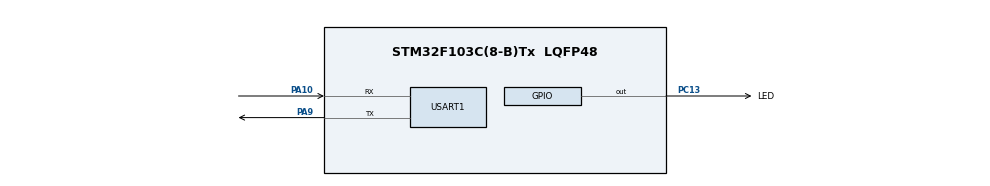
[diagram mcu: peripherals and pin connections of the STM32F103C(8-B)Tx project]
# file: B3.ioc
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Dma.Request0=USART1_TX
Dma.USART1_TX.0.Direction=DMA_MEMORY_TO_PERIPH
Dma.USART1_TX.0.Instance=DMA1_Channel4
Dma.USART1_TX.0.MemDataAlignment=DMA_MDATAALIGN_BYTE
Dma.USART1_TX.0.MemInc=DMA_MINC_ENABLE
Dma.USART1_TX.0.Mode=DMA_NORMAL
Dma.USART1_TX.0.PeriphDataAlignment=DMA_PDATAALIGN_BYTE
Dma.USART1_TX.0.PeriphInc=DMA_PINC_DISABLE
Dma.USART1_TX.0.Priority=DMA_PRIORITY_HIGH
Mcu.Family=STM32F1
Mcu.Name=STM32F103C(8-B)Tx
Mcu.Package=LQFP48
NVIC.DMA1_Channel4_IRQn=true\:0\:0\:false\:false\:true\:false\:true\:true
NVIC.PriorityGroup=NVIC_PRIORITYGROUP_4
NVIC.TIM2_IRQn=true\:0\:0\:false\:false\:true\:true\:true\:true
NVIC.USART1_IRQn=true\:0\:0\:false\:false\:true\:false\:true\:true
PA10.Mode=Asynchronous
PA10.Signal=USART1_RX
PA13.Mode=Serial_Wire
PA13.Signal=SYS_JTMS-SWDIO
PA14.Mode=Serial_Wire
PA14.Signal=SYS_JTCK-SWCLK
PA9.Mode=Asynchronous
PA9.Signal=USART1_TX
PC13-TAMPER-RTC.GPIO_Label=LED
PC13-TAMPER-RTC.GPIO_Speed=GPIO_SPEED_FREQ_MEDIUM
PC13-TAMPER-RTC.Signal=GPIO_Output
ProjectManager.HeapSize=0x200
ProjectManager.StackSize=0x400
ProjectManager.TargetToolchain=STM32CubeIDE
RCC.APB1Freq_Value=8000000
RCC.APB2Freq_Value=8000000
TIM2.AutoReloadPreload=TIM_AUTORELOAD_PRELOAD_ENABLE
TIM2.Period=499
TIM2.Prescaler=7999
USART1.VirtualMode=VM_ASYNC
VP_TIM2_VS_ClockSourceINT.Mode=Internal
board=custom

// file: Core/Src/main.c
/* USER CODE BEGIN Header */
/**
  ******************************************************************************
  * @file           : main.c
  * @brief          : Main program body
  ******************************************************************************
  * @attention
  *
  * Copyright (c) 2026 STMicroelectronics.
  * All rights reserved.
  *
  * This software is licensed under terms that can be found in the LICENSE file
  * in the root directory of this software component.
  * If no LICENSE file comes with this software, it is provided AS-IS.
  *
  ******************************************************************************
  */
/* USER CODE END Header */
#include "main.h"

TIM_HandleTypeDef htim2;

UART_HandleTypeDef huart1;
DMA_HandleTypeDef hdma_usart1_tx;

/* USER CODE BEGIN PV */
uint8_t timer_flag = 0, uart_ready = 1, led_state = 0, rx_data;
uint8_t data[] = "ABCDEFGHIJKLMNOPQRSTUVWXYZ\r\n";
/* USER CODE END PV */

void SystemClock_Config(void);
static void MX_GPIO_Init(void);
static void MX_DMA_Init(void);
static void MX_TIM2_Init(void);
static void MX_USART1_UART_Init(void);

int main(void)
{

  /* MCU Configuration--------------------------------------------------------*/

  /* Reset of all peripherals, Initializes the Flash interface and the Systick. */
  HAL_Init();

  /* Configure the system clock */
  SystemClock_Config();

  /* Initialize all configured peripherals */
  MX_GPIO_Init();
  MX_DMA_Init();
  MX_TIM2_Init();
  MX_USART1_UART_Init();
  /* USER CODE BEGIN 2 */
  HAL_UART_Receive_IT(&huart1, &rx_data, 1);
  /* USER CODE END 2 */

  /* Infinite loop */
  /* USER CODE BEGIN WHILE */
  while (1)
  {
	  if (timer_flag == 1)
	  {
		  timer_flag = 0; // Dua co bao ve 0

		  HAL_GPIO_TogglePin(LED_GPIO_Port, LED_Pin);
		  GPIO_PinState led_state = HAL_GPIO_ReadPin(LED_GPIO_Port, LED_Pin);
		  if (!led_state && uart_ready)
		  {
			  uart_ready = 0;
			  HAL_UART_Transmit_DMA(&huart1, data, sizeof(data)-1);
		  }
	  }
    /* USER CODE END WHILE */

  }
}

void SystemClock_Config(void)
{
  RCC_OscInitTypeDef RCC_OscInitStruct = {0};
  RCC_ClkInitTypeDef RCC_ClkInitStruct = {0};

  /** Initializes the RCC Oscillators according to the specified parameters
  * in the RCC_OscInitTypeDef structure.
  */
  RCC_OscInitStruct.OscillatorType = RCC_OSCILLATORTYPE_HSI;
  RCC_OscInitStruct.HSIState = RCC_HSI_ON;
  RCC_OscInitStruct.HSICalibrationValue = RCC_HSICALIBRATION_DEFAULT;
  RCC_OscInitStruct.PLL.PLLState = RCC_PLL_NONE;
  if (HAL_RCC_OscConfig(&RCC_OscInitStruct) != HAL_OK)
  {
    Error_Handler();
  }

  /** Initializes the CPU, AHB and APB buses clocks
  */
  RCC_ClkInitStruct.ClockType = RCC_CLOCKTYPE_HCLK|RCC_CLOCKTYPE_SYSCLK
                              |RCC_CLOCKTYPE_PCLK1|RCC_CLOCKTYPE_PCLK2;
  RCC_ClkInitStruct.SYSCLKSource = RCC_SYSCLKSOURCE_HSI;
  RCC_ClkInitStruct.AHBCLKDivider = RCC_SYSCLK_DIV1;
  RCC_ClkInitStruct.APB1CLKDivider = RCC_HCLK_DIV1;
  RCC_ClkInitStruct.APB2CLKDivider = RCC_HCLK_DIV1;

  if (HAL_RCC_ClockConfig(&RCC_ClkInitStruct, FLASH_LATENCY_0) != HAL_OK)
  {
    Error_Handler();
  }
}

static void MX_TIM2_Init(void)
{

  TIM_ClockConfigTypeDef sClockSourceConfig = {0};
  TIM_MasterConfigTypeDef sMasterConfig = {0};

  htim2.Instance = TIM2;
  htim2.Init.Prescaler = 8000;
  htim2.Init.CounterMode = TIM_COUNTERMODE_UP;
  htim2.Init.Period = 499;
  htim2.Init.ClockDivision = TIM_CLOCKDIVISION_DIV1;
  htim2.Init.AutoReloadPreload = TIM_AUTORELOAD_PRELOAD_ENABLE;
  if (HAL_TIM_Base_Init(&htim2) != HAL_OK)
  {
    Error_Handler();
  }
  sClockSourceConfig.ClockSource = TIM_CLOCKSOURCE_INTERNAL;
  if (HAL_TIM_ConfigClockSource(&htim2, &sClockSourceConfig) != HAL_OK)
  {
    Error_Handler();
  }
  sMasterConfig.MasterOutputTrigger = TIM_TRGO_RESET;
  sMasterConfig.MasterSlaveMode = TIM_MASTERSLAVEMODE_DISABLE;
  if (HAL_TIMEx_MasterConfigSynchronization(&htim2, &sMasterConfig) != HAL_OK)
  {
    Error_Handler();
  }

}

static void MX_USART1_UART_Init(void)
{

  huart1.Instance = USART1;
  huart1.Init.BaudRate = 115200;
  huart1.Init.WordLength = UART_WORDLENGTH_8B;
  huart1.Init.StopBits = UART_STOPBITS_1;
  huart1.Init.Parity = UART_PARITY_NONE;
  huart1.Init.Mode = UART_MODE_TX_RX;
  huart1.Init.HwFlowCtl = UART_HWCONTROL_NONE;
  huart1.Init.OverSampling = UART_OVERSAMPLING_16;
  if (HAL_UART_Init(&huart1) != HAL_OK)
  {
    Error_Handler();
  }

}

static void MX_DMA_Init(void)
{

  /* DMA controller clock enable */
  __HAL_RCC_DMA1_CLK_ENABLE();

  /* DMA interrupt init */
  /* DMA1_Channel4_IRQn interrupt configuration */
  HAL_NVIC_SetPriority(DMA1_Channel4_IRQn, 0, 0);
  HAL_NVIC_EnableIRQ(DMA1_Channel4_IRQn);

}

static void MX_GPIO_Init(void)
{
  GPIO_InitTypeDef GPIO_InitStruct = {0};

  /* GPIO Ports Clock Enable */
  __HAL_RCC_GPIOC_CLK_ENABLE();
  __HAL_RCC_GPIOA_CLK_ENABLE();

  /*Configure GPIO pin Output Level */
  HAL_GPIO_WritePin(LED_GPIO_Port, LED_Pin, GPIO_PIN_RESET);

  /*Configure GPIO pin : LED_Pin */
  GPIO_InitStruct.Pin = LED_Pin;
  GPIO_InitStruct.Mode = GPIO_MODE_OUTPUT_PP;
  GPIO_InitStruct.Pull = GPIO_NOPULL;
  GPIO_InitStruct.Speed = GPIO_SPEED_FREQ_MEDIUM;
  HAL_GPIO_Init(LED_GPIO_Port, &GPIO_InitStruct);

}

/* USER CODE BEGIN 4 */
void HAL_TIM_PeriodElapsedCallback(TIM_HandleTypeDef *htim)
{
	timer_flag = 1;
}
void HAL_UART_TxCpltCallback(UART_HandleTypeDef *huart)
{
	if (huart->Instance==USART1)
	{
		uart_ready = 1;
	}
}
void HAL_UART_RxCpltCallback(UART_HandleTypeDef *huart)
{
	if (huart->Instance==USART1)
	{
		if (rx_data=='0')
		{
			HAL_TIM_Base_Stop_IT(&htim2);
			HAL_GPIO_WritePin(LED_GPIO_Port, LED_Pin, GPIO_PIN_SET);
		}
		else if (rx_data=='1')
		{
			HAL_TIM_Base_Start_IT(&htim2);
		}
		HAL_UART_Receive_IT(&huart1, &rx_data, 1);
	}
}
/* USER CODE END 4 */

void Error_Handler(void)
{
  __disable_irq();
  while (1)
  {
  }
}
